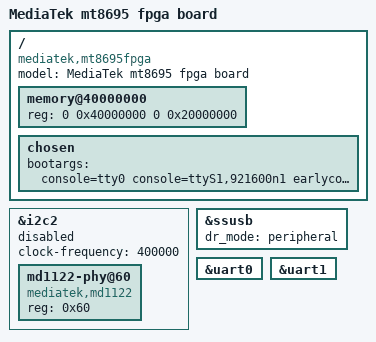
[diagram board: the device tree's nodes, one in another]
/*
 * Copyright (c) 2017 MediaTek Inc.
 * Author: Joe Yang <joe.yang@mediatek.com>
 *
 * This program is free software; you can redistribute it and/or modify
 * it under the terms of the GNU General Public License version 2 as
 * published by the Free Software Foundation.
 *
 * This program is distributed in the hope that it will be useful,
 * but WITHOUT ANY WARRANTY; without even the implied warranty of
 * MERCHANTABILITY or FITNESS FOR A PARTICULAR PURPOSE.  See the
 * GNU General Public License for more details.
 */

/dts-v1/;
#include "mt8695fpga.dtsi"

/ {
	model = "MediaTek mt8695 fpga board";
	compatible = "mediatek,mt8695fpga", "mediatek,mt8695";

	memory@40000000 {
		device_type = "memory";
		reg = <0 0x40000000 0 0x20000000>;
	};

	chosen {
		bootargs = "console=tty0 console=ttyS1,921600n1 \
earlycon=uart8250,mmio32,0x11003000 root=/dev/ram initrd=0x44000000,0x600000 \
loglevel=8 initcall_debug=1 androidboot.selinux=permissive";
	};
};

&i2c2 {
	clock-frequency = <400000>;
	status = "disabled";
	md1122-phy@60 {
		compatible = "mediatek,md1122";
		reg = <0x60>;
	};
};

&ssusb {
	dr_mode = "peripheral"; /* 1: host, 2: device, 3 dual-mode */
	status = "okay";
};

&uart0 {
	status = "okay";
};

&uart1 {
	status = "okay";
};
